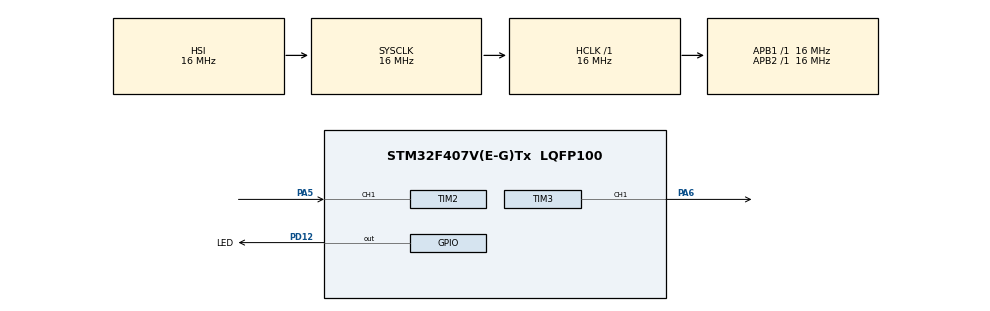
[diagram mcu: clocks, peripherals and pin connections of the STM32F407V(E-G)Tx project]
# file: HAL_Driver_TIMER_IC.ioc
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Mcu.Family=STM32F4
Mcu.Name=STM32F407V(E-G)Tx
Mcu.Package=LQFP100
NVIC.PriorityGroup=NVIC_PRIORITYGROUP_4
NVIC.TIM2_IRQn=true\:0\:0\:false\:false\:true\:true\:true\:true
PA5.Signal=S_TIM2_CH1_ETR
PA6.Signal=S_TIM3_CH1
PD12.GPIO_Label=LED
PD12.Signal=GPIO_Output
ProjectManager.HeapSize=0x200
ProjectManager.StackSize=0x400
ProjectManager.TargetToolchain=STM32CubeIDE
RCC.AHBFreq_Value=16000000
RCC.APB1Freq_Value=16000000
RCC.APB2Freq_Value=16000000
RCC.CortexFreq_Value=16000000
RCC.HSE_VALUE=25000000
RCC.HSI_VALUE=16000000
RCC.LSE_VALUE=32768
RCC.SYSCLKFreq_VALUE=16000000
RCC.VCOOutputFreq_Value=192000000
SH.S_TIM2_CH1_ETR.0=TIM2_CH1,Input_Capture1_from_TI1
SH.S_TIM3_CH1.0=TIM3_CH1,PWM Generation1 CH1
TIM2.Channel-Input_Capture1_from_TI1=TIM_CHANNEL_1
TIM2.ICFilter_CH1=4
TIM2.Prescaler=16 - 1
TIM3.Channel-PWM\ Generation1\ CH1=TIM_CHANNEL_1
TIM3.OCMode_PWM-PWM\ Generation1\ CH1=TIM_OCMODE_PWM2
TIM3.Period=10000 - 1
TIM3.Prescaler=32 - 1
TIM3.Pulse-PWM\ Generation1\ CH1=1000
VP_TIM2_VS_ClockSourceINT.Mode=Internal
VP_TIM3_VS_ClockSourceINT.Mode=Internal
board=custom

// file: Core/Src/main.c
/* USER CODE BEGIN Header */
/**
  ******************************************************************************
  * @file           : main.c
  * @brief          : Main program body
  ******************************************************************************
  * @attention
  *
  * Copyright (c) 2023 STMicroelectronics.
  * All rights reserved.
  *
  * This software is licensed under terms that can be found in the LICENSE file
  * in the root directory of this software component.
  * If no LICENSE file comes with this software, it is provided AS-IS.
  *
  ******************************************************************************
  */
/* USER CODE END Header */
#include "main.h"
#include "tim.h"
#include "gpio.h"

/* USER CODE BEGIN Includes */
#include <stdio.h>
/* USER CODE END Includes */

/* USER CODE BEGIN PM */
uint8_t count = 0;
uint32_t capture[0];
uint8_t dataready = 0;
uint32_t diff;
/* USER CODE END PM */

void SystemClock_Config(void);
/* USER CODE BEGIN PFP */
void HAL_TIM2_IC_CaptureCallback(TIM_HandleTypeDef *htim);

int __io_putchar(int ch) {
	ITM_SendChar(ch);
	return ch;
}
/* USER CODE END PFP */

int main(void)
{

  /* MCU Configuration--------------------------------------------------------*/

  /* Reset of all peripherals, Initializes the Flash interface and the Systick. */
  HAL_Init();

  /* Configure the system clock */
  SystemClock_Config();

  /* Initialize all configured peripherals */
  MX_GPIO_Init();
  MX_TIM2_Init();
  MX_TIM3_Init();
  /* USER CODE BEGIN 2 */
//  TIM2->CCER |= TIM_CCER_CC1E;
//  TIM2->DIER |= TIM_DIER_CC1IE;
//  TIM2->CR1 |= TIM_CR1_CEN;
  HAL_TIM_RegisterCallback(&htim2, HAL_TIM_IC_CAPTURE_CB_ID, HAL_TIM2_IC_CaptureCallback);
  HAL_TIM_IC_Start_IT(&htim2, TIM_CHANNEL_1);
  uint32_t ticks = HAL_GetTick();
  //TIM3->CCER |= TIM_CCER_CC1E;
  //HAL_TIM_PWM_Start(&htim3, TIM_CHANNEL_1);
  float T;
  uint32_t duty  = 1000;
  LL_TIM_CC_EnableChannel(TIM3, LL_TIM_CHANNEL_CH1);
  LL_TIM_EnableCounter(TIM3);
  /* USER CODE END 2 */

  /* Infinite loop */
  while (1)
  {

    /* USER CODE BEGIN 3 */
	  if((HAL_GetTick() - ticks)>=30){
		  ticks = HAL_GetTick();
		  HAL_GPIO_TogglePin(LED_GPIO_Port, LED_Pin);
	  }
	  if(dataready){
		  duty += 100;
		  if(duty > 10000){
			  duty = 100;
		  }
		  //__HAL_TIM_SET_COMPARE(&htim3, TIM_CHANNEL_1, duty);
		  LL_TIM_OC_SetCompareCH1(TIM3, duty);
		  dataready = 0;
		  T = diff * (16.0 / (16E+3));
		  printf("diff: %lu ->%lu\r\n", diff, (uint32_t)T);

	  }
	  HAL_Delay(10);
  }
  /* USER CODE END 3 */
}

void SystemClock_Config(void)
{
  RCC_OscInitTypeDef RCC_OscInitStruct = {0};
  RCC_ClkInitTypeDef RCC_ClkInitStruct = {0};

  /** Configure the main internal regulator output voltage
  */
  __HAL_RCC_PWR_CLK_ENABLE();
  __HAL_PWR_VOLTAGESCALING_CONFIG(PWR_REGULATOR_VOLTAGE_SCALE1);

  /** Initializes the RCC Oscillators according to the specified parameters
  * in the RCC_OscInitTypeDef structure.
  */
  RCC_OscInitStruct.OscillatorType = RCC_OSCILLATORTYPE_HSI;
  RCC_OscInitStruct.HSIState = RCC_HSI_ON;
  RCC_OscInitStruct.HSICalibrationValue = RCC_HSICALIBRATION_DEFAULT;
  RCC_OscInitStruct.PLL.PLLState = RCC_PLL_NONE;
  if (HAL_RCC_OscConfig(&RCC_OscInitStruct) != HAL_OK)
  {
    Error_Handler();
  }

  /** Initializes the CPU, AHB and APB buses clocks
  */
  RCC_ClkInitStruct.ClockType = RCC_CLOCKTYPE_HCLK|RCC_CLOCKTYPE_SYSCLK
                              |RCC_CLOCKTYPE_PCLK1|RCC_CLOCKTYPE_PCLK2;
  RCC_ClkInitStruct.SYSCLKSource = RCC_SYSCLKSOURCE_HSI;
  RCC_ClkInitStruct.AHBCLKDivider = RCC_SYSCLK_DIV1;
  RCC_ClkInitStruct.APB1CLKDivider = RCC_HCLK_DIV1;
  RCC_ClkInitStruct.APB2CLKDivider = RCC_HCLK_DIV1;

  if (HAL_RCC_ClockConfig(&RCC_ClkInitStruct, FLASH_LATENCY_0) != HAL_OK)
  {
    Error_Handler();
  }
}

/* USER CODE BEGIN 4 */
void HAL_TIM2_IC_CaptureCallback(TIM_HandleTypeDef *htim)
{

	if(htim->Channel == HAL_TIM_ACTIVE_CHANNEL_1){
		//todo
		capture[count] = HAL_TIM_ReadCapturedValue(htim, TIM_CHANNEL_1);
		//capture[count] = __HAL_TIM_GET_COMPARE(htim, TIM_CHANNEL_1);
		//capture[count] = htim->Instance->CCR1; //TIM2->CCR1
		count += 1;
		if(count > 1){
			count = 0;
			if(capture[0] < capture[1]){
				diff = capture[1] - capture[0];
			}else{
				diff = __HAL_TIM_GET_AUTORELOAD(htim) - capture[0] + capture[1];
			}
			dataready = 1;
		}
		//

		//frecuencia
	}
}
/* USER CODE END 4 */

void Error_Handler(void)
{
  __disable_irq();
  while (1)
  {
  }
}
